# psoc6_02 register map
Vendor: Cypress Semiconductor; Series: PSoC6_02; File version: 1.0
CPU: CM4 r0p1, little endian, MPU, FPU, VTOR, 3 interrupt priority bits
Registers are 32-bit, read-write, reset 0x0 unless marked. A register's access mark holds for its fields unless they carry their own. Offsets are from the block's base; [hi:lo] are bit positions; lines under a group give offsets from that group; {n}, {i} and the like mark numbered series.

## PROFILE — Energy Profiler IP
Base 0x402D0000
0x00 CTL — Profile control
  [31] ENABLED — Enables the profiling block: '0': Disabled. '1': Enabled.
  [0] WIN_MODE — Specifies the profiling time window mode: '0': Start / stop mode. The profiling time window is started when a rising edge of the start trigger signal occurs and stopped when a rising edge of the stop trigger signal occurs. In case both rising edges (of start and stop trigger signals) occur in the same cycle, the profiling time window is stopped. '1': Enable mode. The profiling time window is active as long as the start 'trigger' signal is active. The stop trigger signal has no effect.
0x04 STATUS ro — Profile status
  [0] WIN_ACTIVE — Indicates if the profiling time window is active. '0': Not active. '1': Active.
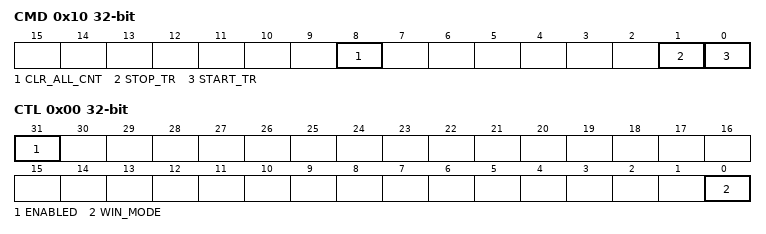
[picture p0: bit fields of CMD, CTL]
0x10 CMD — Profile command
  [8] CLR_ALL_CNT — Counter clear. When written with '1', all profiling counter registers are cleared to 0x00.
  [1] STOP_TR — Software stop trigger for the profiling time window. When written with '1', the profiling time window is stopped. Can only be used in start / stop mode (PROFILE_WIN_MODE=0). Has no effect in enable mode (PROFILE_WIN_MODE=1).
  [0] START_TR — Software start trigger for the profiling time window. When written with '1', the profiling time window is started. Can only be used in start / stop mode (PROFILE_WIN_MODE=0). Has no effect in enable mode (PROFILE_WIN_MODE=1).
0x7C0 INTR — Profile interrupt
  [31:0] CNT_OVFLW — This interrupt cause field is activated (HW sets the field to '1') when an profiling counter overflow (from 0xFFFFFFFF to 0x00000000) is captured. There is one bit per profling counter. SW writes a '1' to a bit of this field to clear this bit to '0' (writing 0xFFFFFFFF clears all interrupt causes to '0').
0x7C4 INTR_SET — Profile interrupt set
  [31:0] CNT_OVFLW — SW writes a '1' to a bit of this field to set the corresponding bit in the INTR register.
0x7C8 INTR_MASK — Profile interrupt mask
  [31:0] CNT_OVFLW — Mask bit for corresponding field in the INTR register.
0x7CC INTR_MASKED ro — Profile interrupt masked
  [31:0] CNT_OVFLW — Logical and of corresponding INTR and INTR_MASK fields.
{0x800+0x10*i} CNT_STRUCT[{i}] (i=0..7) group — Profile counter structure
  0x00 CTL — Profile counter configuration
    [31] ENABLED — Enables the profiling counter: '0': Disabled. '1': Enabled.
    [22:16] MON_SEL — This field specifies the montior input signal to be observed by the profiling counter. The monitor signals are product specific, see product definition spreadsheet tab 'Monitor' for details.
    [6:4] REF_CLK_SEL — This field specifies the reference clock used for a counting time base when counting durations. Has no effect when CTL.CNT_DURATION=0.
      0=CLK_TIMER (Timer clock (divided or undivided high frequency clock, e.g. from IMO). Selection is done in SRSS register CLK_TIMER_CTL.TIMER_SEL.); 1=CLK_IMO (IMO - Internal Main Oscillator); 2=CLK_ECO (ECO - External-Crystal Oscillator); 3=CLK_LF (Low frequency clock (ILO, WCO or ALTLF). Selection is done in SRSS register CLK_SELECT.LFCLK_SEL.); 4=CLK_HF (High frequuency clock ('clk_hfx').); 5=CLK_PERI (Peripheral clock ('clk_peri').); 6=RSVD_6 (N/A); 7=RSVD_7 (N/A)
    [0] CNT_DURATION — This field specifies if events (edges) or a duration of the monitor signal is counted. '0': Events are monitored. An edge detection is done. All edges of the selected monitor signal are counted. '1': A duration is monitored. No edge detection is done. The monitored signal is taken as a (high active) level signal for enabling the profiling counter. Note: All monitor signals which only can represent events are edge encoded in hardware, therefore a selection of CTL.CNT_DURATION=1 will not produce meaningful results.
  0x08 CNT — Profile counter value
    [31:0] CNT — This field shows / specifies the actual value of the profiling counter. It allows reading as well as writing the profiling counter.

## Notices in the file
(c) (2016-2021), Cypress Semiconductor Corporation (an Infineon company)
or an affiliate of Cypress Semiconductor Corporation.
SPDX-License-Identifier: Apache-2.0
Licensed under the Apache License, Version 2.0 (the "License");
you may not use this file except in compliance with the License.
You may obtain a copy of the License at
http://www.apache.org/licenses/LICENSE-2.0
Unless required by applicable law or agreed to in writing, software
distributed under the License is distributed on an "AS IS" BASIS,
WITHOUT WARRANTIES OR CONDITIONS OF ANY KIND, either express or implied.
See the License for the specific language governing permissions and
limitations under the License.
